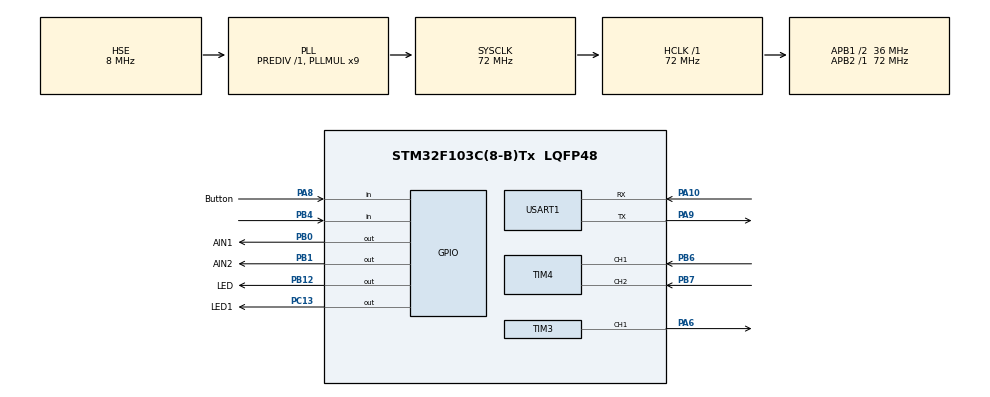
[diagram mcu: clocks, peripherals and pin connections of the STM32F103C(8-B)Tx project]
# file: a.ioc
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Mcu.Family=STM32F1
Mcu.Name=STM32F103C(8-B)Tx
Mcu.Package=LQFP48
NVIC.PriorityGroup=NVIC_PRIORITYGROUP_4
NVIC.USART1_IRQn=true\:0\:0\:false\:false\:true\:true\:true\:true
PA10.Mode=Asynchronous
PA10.Signal=USART1_RX
PA13.Mode=Serial_Wire
PA13.Signal=SYS_JTMS-SWDIO
PA14.Mode=Serial_Wire
PA14.Signal=SYS_JTCK-SWCLK
PA6.Signal=S_TIM3_CH1
PA8.GPIO_Label=Button
PA8.Signal=GPIO_Input
PA9.Mode=Asynchronous
PA9.Signal=USART1_TX
PB0.GPIO_Label=AIN1
PB0.Signal=GPIO_Output
PB1.GPIO_Label=AIN2
PB1.Signal=GPIO_Output
PB12.GPIO_Label=LED
PB12.GPIO_Speed=GPIO_SPEED_FREQ_HIGH
PB12.Signal=GPIO_Output
PB4.Signal=GPIO_Input
PB6.Signal=S_TIM4_CH1
PB7.Signal=S_TIM4_CH2
PC13-TAMPER-RTC.GPIO_Label=LED1
PC13-TAMPER-RTC.Signal=GPIO_Output
PD0-OSC_IN.Mode=HSE-External-Oscillator
PD0-OSC_IN.Signal=RCC_OSC_IN
PD1-OSC_OUT.Mode=HSE-External-Oscillator
PD1-OSC_OUT.Signal=RCC_OSC_OUT
ProjectManager.HeapSize=0x200
ProjectManager.StackSize=0x400
ProjectManager.TargetToolchain=Makefile
RCC.AHBFreq_Value=72000000
RCC.APB1CLKDivider=RCC_HCLK_DIV2
RCC.APB1Freq_Value=36000000
RCC.APB1TimFreq_Value=72000000
RCC.APB2Freq_Value=72000000
RCC.APB2TimFreq_Value=72000000
RCC.HCLKFreq_Value=72000000
RCC.PLLMUL=RCC_PLL_MUL9
RCC.PLLSourceVirtual=RCC_PLLSOURCE_HSE
RCC.SYSCLKFreq_VALUE=72000000
RCC.SYSCLKSource=RCC_SYSCLKSOURCE_PLLCLK
RCC.USBFreq_Value=72000000
SH.S_TIM3_CH1.0=TIM3_CH1,PWM Generation1 CH1
SH.S_TIM4_CH1.0=TIM4_CH1,Encoder_Interface
SH.S_TIM4_CH2.0=TIM4_CH2,Encoder_Interface
TIM3.Channel-PWM\ Generation1\ CH1=TIM_CHANNEL_1
TIM3.Period=1000-1
TIM3.Prescaler=3-1
TIM3.Pulse-PWM\ Generation1\ CH1=499
TIM4.EncoderMode=TIM_ENCODERMODE_TI12
TIM4.IC1Filter=6
TIM4.IC2Filter=6
USART1.VirtualMode=VM_ASYNC
VP_TIM3_VS_ClockSourceINT.Mode=Internal
board=custom

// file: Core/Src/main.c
/* USER CODE BEGIN Header */
/**
  ******************************************************************************
  * @file           : main.c
  * @brief          : Main program body
  ******************************************************************************
  * @attention
  *
  * Copyright (c) 2024 STMicroelectronics.
  * All rights reserved.
  *
  * This software is licensed under terms that can be found in the LICENSE file
  * in the root directory of this software component.
  * If no LICENSE file comes with this software, it is provided AS-IS.
  *
  ******************************************************************************
  */
/* USER CODE END Header */
#include "main.h"
#include "tim.h"
#include "usart.h"
#include "gpio.h"

/* USER CODE BEGIN Includes */
#include "button.h"
#include "encoder.h"
/* USER CODE END Includes */

void SystemClock_Config(void);

/* USER CODE BEGIN 0 */
int iTempTim4Encoder ; //临时存储TIM4编码器接口捕获的脉冲�??
/* USER CODE END 0 */

int main(void)
{

  /* MCU Configuration--------------------------------------------------------*/

  /* Reset of all peripherals, Initializes the Flash interface and the Systick. */
  HAL_Init();

  /* Configure the system clock */
  SystemClock_Config();

  /* Initialize all configured peripherals */
  MX_GPIO_Init();
  MX_USART1_UART_Init();
  MX_TIM4_Init();
  MX_TIM3_Init();
  /* USER CODE BEGIN 2 */
  HAL_TIM_Encoder_Start(&htim4, TIM_CHANNEL_ALL); //启动TIM4编码�?
  HAL_TIM_PWM_Start(&htim3, TIM_CHANNEL_1); //启动TIM3 PWM
  HAL_GPIO_WritePin(AIN1_GPIO_Port, AIN1_Pin, GPIO_PIN_SET); //设置AIN1引脚为高电平
  HAL_GPIO_WritePin(AIN2_GPIO_Port, AIN2_Pin, GPIO_PIN_RESET); //设置AIN2引脚为低电平

  /* USER CODE END 2 */

  /* Infinite loop */
  /* USER CODE BEGIN WHILE */
  while (1)
  {
    HAL_Delay(5000);
    __HAL_TIM_SET_COMPARE(&htim3, TIM_CHANNEL_1, 200); //设置PWM占空比为50%

    iTempTim4Encoder = GetTim4Encoder(); //获取TIM4编码器接口捕获的脉冲�??
    HAL_UART_Transmit(&huart1, (uint8_t*)&iTempTim4Encoder, 1, 0xFFFF);

    /* USER CODE END WHILE */

    /* USER CODE BEGIN 3 */

    HAL_GPIO_TogglePin(LED1_GPIO_Port,LED1_Pin);
  }
  /* USER CODE END 3 */
}

void SystemClock_Config(void)
{
  RCC_OscInitTypeDef RCC_OscInitStruct = {0};
  RCC_ClkInitTypeDef RCC_ClkInitStruct = {0};

  /** Initializes the RCC Oscillators according to the specified parameters
  * in the RCC_OscInitTypeDef structure.
  */
  RCC_OscInitStruct.OscillatorType = RCC_OSCILLATORTYPE_HSE;
  RCC_OscInitStruct.HSEState = RCC_HSE_ON;
  RCC_OscInitStruct.HSEPredivValue = RCC_HSE_PREDIV_DIV1;
  RCC_OscInitStruct.HSIState = RCC_HSI_ON;
  RCC_OscInitStruct.PLL.PLLState = RCC_PLL_ON;
  RCC_OscInitStruct.PLL.PLLSource = RCC_PLLSOURCE_HSE;
  RCC_OscInitStruct.PLL.PLLMUL = RCC_PLL_MUL9;
  if (HAL_RCC_OscConfig(&RCC_OscInitStruct) != HAL_OK)
  {
    Error_Handler();
  }

  /** Initializes the CPU, AHB and APB buses clocks
  */
  RCC_ClkInitStruct.ClockType = RCC_CLOCKTYPE_HCLK|RCC_CLOCKTYPE_SYSCLK
                              |RCC_CLOCKTYPE_PCLK1|RCC_CLOCKTYPE_PCLK2;
  RCC_ClkInitStruct.SYSCLKSource = RCC_SYSCLKSOURCE_PLLCLK;
  RCC_ClkInitStruct.AHBCLKDivider = RCC_SYSCLK_DIV1;
  RCC_ClkInitStruct.APB1CLKDivider = RCC_HCLK_DIV2;
  RCC_ClkInitStruct.APB2CLKDivider = RCC_HCLK_DIV1;

  if (HAL_RCC_ClockConfig(&RCC_ClkInitStruct, FLASH_LATENCY_2) != HAL_OK)
  {
    Error_Handler();
  }
}

void Error_Handler(void)
{
  __disable_irq();
  while (1)
  {
  }
}
